# AS32x601 register map
File version: 1.0
CPU: RISC-V, little endian
Registers are 32-bit, read-write, reset 0x0 unless marked. A register's access mark holds for its fields unless they carry their own. Offsets are from the block's base; [hi:lo] are bit positions; lines under a group give offsets from that group; {n}, {i} and the like mark numbered series.

## MAC — Media Access Control (MAC) Controller
Base 0x50000000
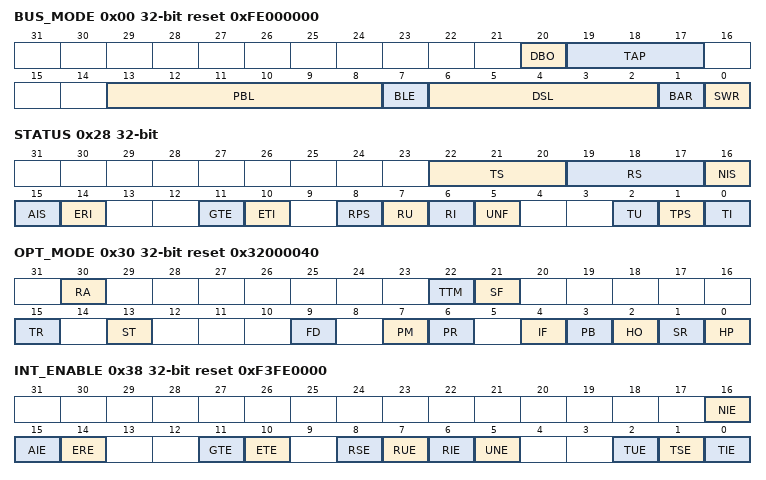
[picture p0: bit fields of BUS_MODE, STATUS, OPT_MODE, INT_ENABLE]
0x00 BUS_MODE reset 0xFE000000
  [20] DBO — Descriptor Byte Order
  [19:17] TAP — Transmit Automatic Polling [2:0]
  [13:8] PBL — Programmable Burst Length [5:0]
  [7] BLE — Big-Endian and Little-Endian Select
  [6:2] DSL — Descriptor Skip Length [4:0]
  [1] BAR — BUS Arbitration
  [0] SWR — Software Reset
0x08 TX_POLL — Transmit Poll Demand register
  [31:0] RPD — Send Poll Descriptor
0x10 RX_POLL — Receive Poll Demand register
  [31:0] RPD — Receive Poll Descriptor
0x18 RDES_BASE_ADDR reset 0xFFFFFFFF — Receive Descriptor List Address register
  [31:0] LAD — Receive List Address Start
0x20 TDES_BASE_ADDR reset 0xFFFFFFFF — Transmit Descriptor List Address register
  [31:0] LAD — Transmit List Address Start
0x28 STATUS
  [22:20] TS — Transmit Process State [2:0]
  [19:17] RS — Receive Process State [2:0]
  [16] NIS — Normal Interrupt Summary
  [15] AIS — Abnormal Interrupt Summary
  [14] ERI — Early Receive Interrupt
  [11] GTE — General Timer Expiry
  [10] ETI — Early Transmit Interrupt
  [8] RPS — Receive Process Stopped
  [7] RU — Receive Buffer Unavailable
  [6] RI — Receive Interrupt
  [5] UNF — Transmit Underflow
  [2] TU — Transmit Buffer Unavailable
  [1] TPS — Transmit Process Stopped
  [0] TI — Transmit Interrupt
0x30 OPT_MODE reset 0x32000040 — Operation Mode register
  [30] RA — Receive All
  [22] TTM — Transmit Threshold Mode
  [21] SF — Store and Forward
  [15] TR — Threshold Control Bit
  [13] ST — Start/Stop Transmission Command
  [9] FD — Full Duplex Mode
  [7] PM — Pass All Multicast
  [6] PR — Promiscuous Mode
  [4] IF — Inverse Filtering (Read Only)
  [3] PB — Pass Bad Frames
  [2] HO — Hash Only Filter Mode (Read Only)
  [1] SR — Start/Stop Receive Command
  [0] HP — Hash/Perfect Filter Mode (Read Only)
0x38 INT_ENABLE reset 0xF3FE0000 — Interrupt Enable register
  [16] NIE — Normal Interrupt Summary Enable
  [15] AIE — Abnormal Interrupt Enable
  [14] ERE — Early Receive Interrupt Enable
  [11] GTE — General Timer Expiry Interrupt Enable
  [10] ETE — Early Transmit Interrupt Enable
  [8] RSE — Receive Stop Interrupt Enable
  [7] RUE — Receive Buffer Unavailable Interrupt Enable
  [6] RIE — Receive Interrupt Enable
  [5] UNE — Transmit Underflow Interrupt Enable
  [2] TUE — Transmit Buffer Unavailable Interrupt Enable
  [1] TSE — Transmit Stop Interrupt Enable
  [0] TIE — Transmit Interrupt Enable
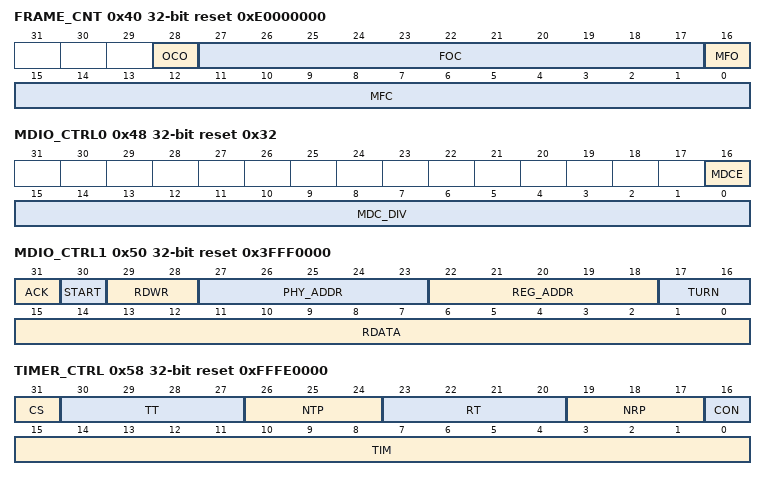
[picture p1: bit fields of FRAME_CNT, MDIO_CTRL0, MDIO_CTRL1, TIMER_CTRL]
0x40 FRAME_CNT ro reset 0xE0000000 — Frame and Counter Overflow register
  [28] OCO — Overflow Counter Overflow (Read Only)
  [27:17] FOC — FIFO Overflow Counter (Read Only)
  [16] MFO — Missed Frame Overflow (Read Only)
  [15:0] MFC — Missed Frame Counter (Read Only)
0x48 MDIO_CTRL0 reset 0x32 — MDIO Control register 0
  [16] MDCE — MDIO Enable
  [15:0] MDC_DIV — MDC Divider
0x50 MDIO_CTRL1 reset 0x3FFF0000 — MDIO Control register 1
  [31] ACK — Acknowledge Signal
  [30] START — Start bit
  [29:28] RDWR — Read/Write Flag [1:0]
  [27:23] PHY_ADDR — PHY Address
  [22:18] REG_ADDR — PHY Register Address
  [17:16] TURN — MDIO Turnaround Time [1:0]
  [15:0] RDATA — MDIO Read Data
0x58 TIMER_CTRL reset 0xFFFE0000 — General Timer and Interrupt Suppression Control register
  [31] CS — Cycle Size
  [30:27] TT — Transmit Timer [3:0]
  [26:24] NTP — Number of Transmitted Packets [2:0]
  [23:20] RT — Receive Timer [3:0]
  [19:17] NRP — Number of Received Packets [2:0]
  [16] CON — Continuous Mode
  [15:0] TIM — Timer Value [15:0]

## DMA0 — General Purpose DMA Controller 0
Base 0x30004000
Same registers: DMA1 0x30004400
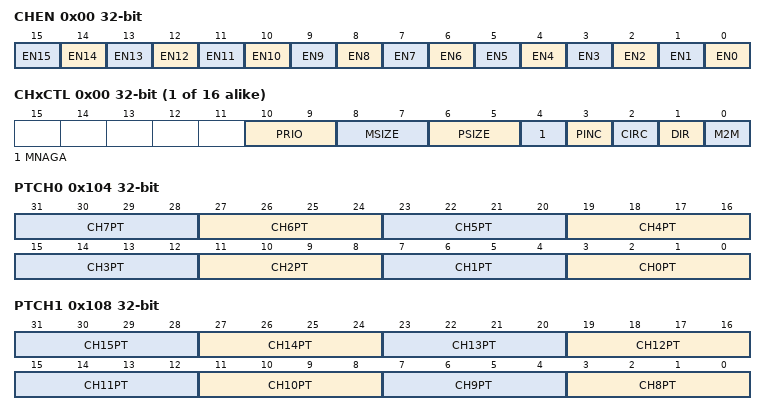
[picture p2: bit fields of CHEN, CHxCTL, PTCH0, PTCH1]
0x00 CHEN — DMA channel enable register
  [n] EN{n} (n=0..15) — DMA channel {n} enable
{0x4+0x10*i} DMA_Channel[{i}] (i=0..15) group — General Purpose DMA channel registers (16 pairs)
  0x00 CHxCTL — DMA channel x configuration register
    [10:9] PRIO — DMA channel x priority level
    [8:7] MSIZE — DMA channel x memory data width
    [6:5] PSIZE — DMA channel x peripheral data width
    [4] MNAGA — DMA channel x memory address increment
    [3] PINC — DMA channel x peripheral address increment
    [2] CIRC — DMA channel x circular mode
    [1] DIR — DMA channel x data transfer direction
    [0] M2M — DMA channel x memory-to-memory transfer mode
  0x04 CHxCNT — DMA channel x number of data register
    [15:0] CNT — Channel x number of data to transfer
  0x08 CHxPADDR — DMA channel x peripheral address register
    [31:0] PADDR — Channel x peripheral address
  0x0C CHxMADDR — DMA channel x memory address register
    [31:0] MADDR — Channel x memory address
0x104 PTCH0 — DMA peripheral interface register0
  [4n+3:4n] CH{n}PT (n=0..7) — DMA channel {n} peripheral interface
0x108 PTCH1 — DMA peripheral interface register1
  [4n-29:4n-32] CH{n}PT (n=8..15) — DMA channel {n} peripheral interface
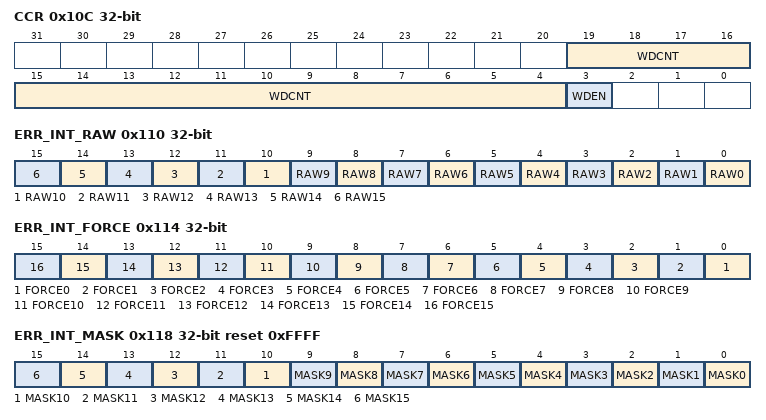
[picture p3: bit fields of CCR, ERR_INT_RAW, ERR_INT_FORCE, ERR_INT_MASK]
0x10C CCR — DMA control and status register
  [19:4] WDCNT — Watchdog threshold
  [3] WDEN — Watch dog enable
0x110 ERR_INT_RAW — DMA error interrupt raw status register
  [n] RAW{n} (n=0..15) — DMA channel {n} error interrupt raw status
0x114 ERR_INT_FORCE — DMA error interrupt force register
  [n] FORCE{n} (n=0..15) — DMA channel {n} error interrupt force
0x118 ERR_INT_MASK reset 0xFFFF — DMA error interrupt mask register
  [n] MASK{n} (n=0..15) — DMA channel {n} error interrupt mask
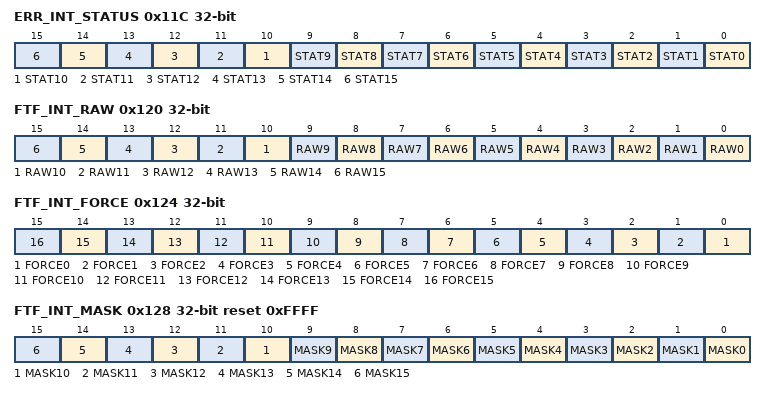
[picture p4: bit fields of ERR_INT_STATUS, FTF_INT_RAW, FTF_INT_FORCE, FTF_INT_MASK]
0x11C ERR_INT_STATUS — DMA error interrupt status register
  [n] STAT{n} (n=0..15) — DMA channel {n} error interrupt status
0x120 FTF_INT_RAW — DMA full transfer interrupt raw status register
  [n] RAW{n} (n=0..15) — DMA channel {n} tranfer commplete interrupt raw status
0x124 FTF_INT_FORCE — DMA full transfer interrupt force register
  [n] FORCE{n} (n=0..15) — DMA channel {n} tranfer commplete interrupt force
0x128 FTF_INT_MASK reset 0xFFFF — DMA full transfer interrupt mask register
  [n] MASK{n} (n=0..15) — DMA channel {n} tranfer commplete interrupt mask
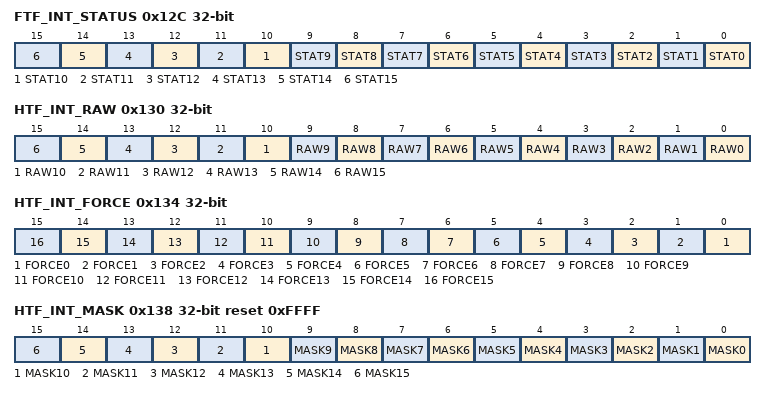
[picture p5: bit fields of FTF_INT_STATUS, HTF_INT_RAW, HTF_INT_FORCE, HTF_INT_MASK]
0x12C FTF_INT_STATUS — DMA full transfer interrupt status register
  [n] STAT{n} (n=0..15) — DMA channel {n} tranfer commplete interrupt status
0x130 HTF_INT_RAW — DMA half transfer interrupt raw status register
  [n] RAW{n} (n=0..15) — DMA channel {n} half tranfer interrput raw status
0x134 HTF_INT_FORCE — DMA half transfer interrupt force register
  [n] FORCE{n} (n=0..15) — DMA channel {n} half tranfer interrput force
0x138 HTF_INT_MASK reset 0xFFFF — DMA half transfer interrupt mask register
  [n] MASK{n} (n=0..15) — DMA channel {n} half tranfer interrput mask
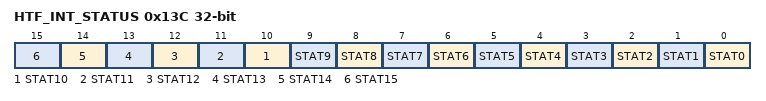
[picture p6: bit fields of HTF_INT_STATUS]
0x13C HTF_INT_STATUS — DMA half transfer interrupt status register
  [n] STAT{n} (n=0..15) — DMA channel {n} half tranfer interrput status
0x140 WDG_INT_RAW — DMA watchdog interrupt raw status register
  [0] RAW — DMA watch dog interrput raw status
0x144 WDG_INT_FORCE — DMA watchdog interrupt force register
  [0] FORCE — DMA watch dog interrput force
0x148 WDG_INT_MASK — DMA watchdog interrupt mask register
  [0] MASK — DMA watch dog interrput mask
0x14C WDG_INT_STATUS — DMA watchdog interrupt status register
  [0] STAT — DMA watch dog interrput status
